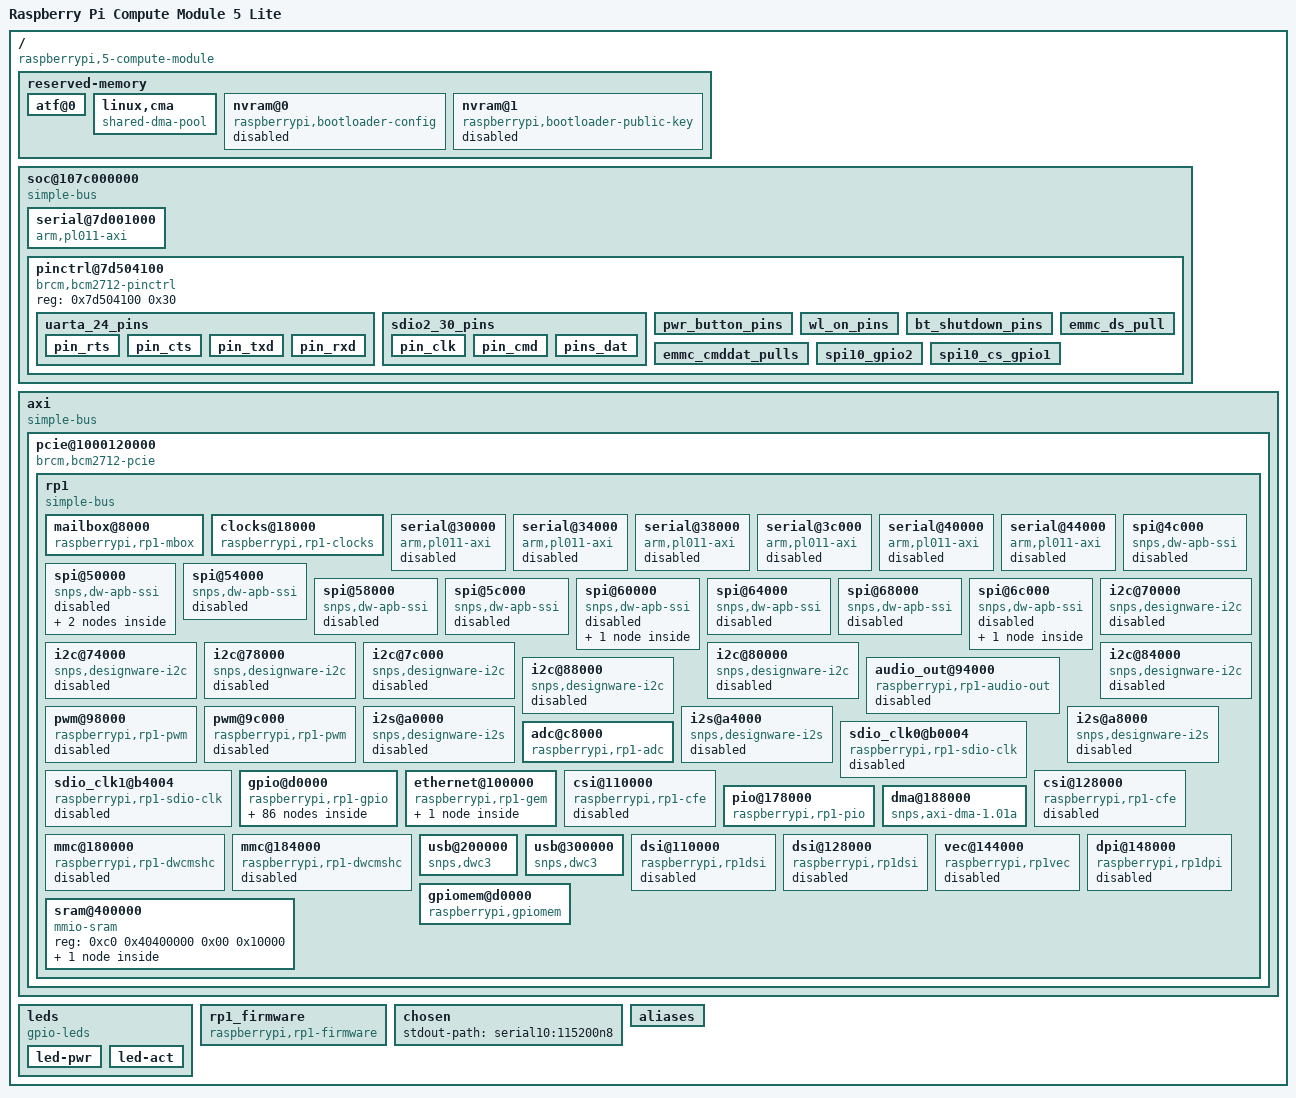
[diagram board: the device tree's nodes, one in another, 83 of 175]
/dts-v1/;
/*
 * Reduced stock Raspberry Pi CM5 Lite board DTB (bcm2712-rpi-cm5l-cm5io.dtb as the firmware ships
 * it; the upstream sources are GPL-2.0 OR MIT), decompiled with dtc. Kept: the root properties,
 * /reserved-memory, /axi/pcie@1000120000 with the whole RP1 subtree, the BCM2712 UART10 console
 * and pinctrl@7d504100, /leds, /rp1_firmware, /chosen stdout-path, and the /aliases and
 * /__symbols__ entries that point into them. Everything else is dropped, so phandles to removed
 * nodes (clocks, regulators, interrupt controllers outside RP1) dangle on purpose: the ownership
 * checks must not need them. Compile without -@ (the __symbols__ node is part of the source).
 */

/ {
	compatible = "raspberrypi,5-compute-module", "brcm,bcm2712";
	#address-cells = <0x02>;
	#size-cells = <0x01>;
	interrupt-parent = <0x01>;
	model = "Raspberry Pi Compute Module 5 Lite";
	reserved-memory {
		ranges;
		#address-cells = <0x02>;
		#size-cells = <0x01>;
		phandle = <0x80>;
		atf@0 {
			reg = <0x00 0x00 0x80000>;
			no-map;
		};
		linux,cma {
			compatible = "shared-dma-pool";
			size = <0x4000000>;
			reusable;
			linux,cma-default;
			alloc-ranges = <0x00 0x00 0x40000000>;
			phandle = <0x81>;
		};
		nvram@0 {
			compatible = "raspberrypi,bootloader-config", "nvmem-rmem";
			#address-cells = <0x01>;
			#size-cells = <0x01>;
			reg = <0x00 0x00 0x00>;
			no-map;
			status = "disabled";
			phandle = <0x82>;
		};
		nvram@1 {
			compatible = "raspberrypi,bootloader-public-key", "nvmem-rmem";
			#address-cells = <0x01>;
			#size-cells = <0x01>;
			reg = <0x00 0x00 0x00>;
			no-map;
			status = "disabled";
			phandle = <0x83>;
		};
	};
	soc@107c000000 {
		compatible = "simple-bus";
		ranges = <0x00 0x10 0x00 0x80000000>;
		#address-cells = <0x01>;
		#size-cells = <0x01>;
		phandle = <0x84>;
		serial@7d001000 {
			compatible = "arm,pl011-axi";
			reg = <0x7d001000 0x200>;
			interrupts = <0x00 0x79 0x04>;
			clocks = <0x0d 0x0e>;
			clock-names = "uartclk", "apb_pclk";
			arm,primecell-periphid = <0x341011>;
			status = "okay";
			phandle = <0x87>;
		};
		pinctrl@7d504100 {
			compatible = "brcm,bcm2712-pinctrl";
			reg = <0x7d504100 0x30>;
			phandle = <0x91>;
			uarta_24_pins {
				phandle = <0x1f>;
				pin_rts {
					function = "uart0";
					pins = "gpio24";
					bias-disable;
				};
				pin_cts {
					function = "uart0";
					pins = "gpio25";
					bias-pull-up;
				};
				pin_txd {
					function = "uart0";
					pins = "gpio26";
					bias-disable;
				};
				pin_rxd {
					function = "uart0";
					pins = "gpio27";
					bias-pull-up;
				};
			};
			sdio2_30_pins {
				phandle = <0x49>;
				pin_clk {
					function = "sd2";
					pins = "gpio30";
					bias-disable;
				};
				pin_cmd {
					function = "sd2";
					pins = "gpio31";
					bias-pull-up;
				};
				pins_dat {
					function = "sd2";
					pins = "gpio32", "gpio33", "gpio34", "gpio35";
					bias-pull-up;
				};
			};
			pwr_button_pins {
				function = "gpio";
				pins = "gpio20";
				bias-pull-up;
				phandle = <0x76>;
			};
			wl_on_pins {
				function = "gpio";
				pins = "gpio28";
				phandle = <0x5b>;
			};
			bt_shutdown_pins {
				function = "gpio";
				pins = "gpio29";
				phandle = <0x20>;
			};
			emmc_ds_pull {
				pins = "emmc_ds";
				bias-pull-down;
				phandle = <0x0a>;
			};
			emmc_cmddat_pulls {
				pins = "emmc_cmd", "emmc_dat0", "emmc_dat1", "emmc_dat2", "emmc_dat3", "emmc_dat4", "emmc_dat5", "emmc_dat6", "emmc_dat7";
				bias-pull-up;
				phandle = <0x09>;
			};
			spi10_gpio2 {
				function = "vc_spi0";
				pins = "gpio2", "gpio3", "gpio4";
				bias-disable;
				phandle = <0x1b>;
			};
			spi10_cs_gpio1 {
				function = "gpio";
				pins = "gpio1";
				bias-pull-up;
				phandle = <0x1c>;
			};
		};
	};
	axi {
		compatible = "simple-bus";
		#address-cells = <0x02>;
		#size-cells = <0x02>;
		ranges = <0x00 0x00 0x00 0x00 0x10 0x00 0x10 0x00 0x10 0x00 0x01 0x00 0x14 0x00 0x14 0x00 0x04 0x00 0x18 0x00 0x18 0x00 0x04 0x00 0x1c 0x00 0x1c 0x00 0x04 0x00>;
		dma-ranges = <0x00 0x00 0x00 0x00 0x10 0x00 0x10 0x00 0x10 0x00 0x01 0x00 0x14 0x00 0x14 0x00 0x04 0x00 0x18 0x00 0x18 0x00 0x04 0x00 0x1c 0x00 0x1c 0x00 0x04 0x00>;
		phandle = <0xa4>;
		pcie@1000120000 {
			compatible = "brcm,bcm2712-pcie";
			reg = <0x10 0x120000 0x00 0x9310>;
			device_type = "pci";
			linux,pci-domain = <0x02>;
			max-link-speed = <0x02>;
			num-lanes = <0x04>;
			#address-cells = <0x03>;
			#interrupt-cells = <0x01>;
			#size-cells = <0x02>;
			interrupt-parent = <0x01>;
			interrupts = <0x00 0xe9 0x04 0x00 0xea 0x04>;
			interrupt-names = "pcie", "msi";
			interrupt-map-mask = <0x00 0x00 0x00 0x07>;
			interrupt-map = <0x00 0x00 0x00 0x01 0x01 0x00 0xe5 0x04 0x00 0x00 0x00 0x02 0x01 0x00 0xe6 0x04 0x00 0x00 0x00 0x03 0x01 0x00 0xe7 0x04 0x00 0x00 0x00 0x04 0x01 0x00 0xe8 0x04>;
			resets = <0x22 0x23 0x2c>;
			reset-names = "rescal", "bridge";
			msi-controller;
			msi-parent = <0x26>;
			ranges = <0x2000000 0x00 0x00 0x1f 0x00 0x00 0xfffffffc 0x43000000 0x04 0x00 0x1c 0x00 0x03 0x00>;
			dma-ranges = <0x2000000 0x00 0x00 0x1f 0x00 0x00 0x400000 0x43000000 0x10 0x00 0x00 0x00 0x10 0x00 0x3000000 0xff 0xfffff000 0x10 0x130000 0x00 0x1000>;
			status = "okay";
			brcm,vdm-qos-map = <0x8080809 0xa0a0b0b>;
			aspm-no-l0s;
			phandle = <0xa6>;
			rp1 {
				compatible = "simple-bus";
				#address-cells = <0x02>;
				#size-cells = <0x02>;
				#interrupt-cells = <0x02>;
				interrupt-controller;
				interrupt-parent = <0x27>;
				ranges = <0xc0 0x40000000 0x2000000 0x00 0x00 0x00 0x410000>;
				dma-ranges = <0x10 0x00 0x43000000 0x10 0x00 0x10 0x00 0xc0 0x40000000 0x2000000 0x00 0x00 0x00 0x410000 0x00 0x00 0x2000000 0x10 0x00 0x10 0x00>;
				phandle = <0x27>;
				mailbox@8000 {
					compatible = "raspberrypi,rp1-mbox";
					status = "okay";
					reg = <0xc0 0x40008000 0x00 0x4000>;
					interrupts = <0x3a 0x04>;
					#mbox-cells = <0x01>;
					phandle = <0x5c>;
				};
				clocks@18000 {
					compatible = "raspberrypi,rp1-clocks";
					#clock-cells = <0x01>;
					reg = <0xc0 0x40018000 0x00 0x10038>;
					clocks = <0x28>;
					assigned-clocks = <0x02 0x00 0x02 0x01 0x02 0x03 0x02 0x09 0x02 0x10 0x02 0x04 0x02 0x0a 0x02 0x0c 0x02 0x06 0x02 0x0d 0x02 0x1f 0x02 0x20 0x02 0x1d>;
					assigned-clock-rates = <0x3b9aca00 0x5b8d8000 0xbebc200 0x7735940 0x7735940 0x3a98000 0x927c000 0xbebc200 0x5f5e100 0x2faf080 0xf4240 0xbebc200 0x2faf080>;
					phandle = <0x02>;
				};
				serial@30000 {
					compatible = "arm,pl011-axi";
					reg = <0xc0 0x40030000 0x00 0x100>;
					interrupts = <0x19 0x04>;
					clocks = <0x02 0x0f 0x02 0x06>;
					clock-names = "uartclk", "apb_pclk";
					pinctrl-names = "default";
					arm,primecell-periphid = <0x341011>;
					uart-has-rtscts;
					cts-event-workaround;
					skip-init;
					status = "disabled";
					pinctrl-0 = <0x29>;
					phandle = <0x70>;
				};
				serial@34000 {
					compatible = "arm,pl011-axi";
					reg = <0xc0 0x40034000 0x00 0x100>;
					interrupts = <0x2a 0x04>;
					clocks = <0x02 0x0f 0x02 0x06>;
					clock-names = "uartclk", "apb_pclk";
					pinctrl-names = "default";
					arm,primecell-periphid = <0x341011>;
					uart-has-rtscts;
					cts-event-workaround;
					skip-init;
					status = "disabled";
					phandle = <0xa7>;
				};
				serial@38000 {
					compatible = "arm,pl011-axi";
					reg = <0xc0 0x40038000 0x00 0x100>;
					interrupts = <0x2b 0x04>;
					clocks = <0x02 0x0f 0x02 0x06>;
					clock-names = "uartclk", "apb_pclk";
					pinctrl-names = "default";
					arm,primecell-periphid = <0x341011>;
					uart-has-rtscts;
					cts-event-workaround;
					skip-init;
					status = "disabled";
					phandle = <0xa8>;
				};
				serial@3c000 {
					compatible = "arm,pl011-axi";
					reg = <0xc0 0x4003c000 0x00 0x100>;
					interrupts = <0x2c 0x04>;
					clocks = <0x02 0x0f 0x02 0x06>;
					clock-names = "uartclk", "apb_pclk";
					pinctrl-names = "default";
					arm,primecell-periphid = <0x341011>;
					uart-has-rtscts;
					cts-event-workaround;
					skip-init;
					status = "disabled";
					phandle = <0xa9>;
				};
				serial@40000 {
					compatible = "arm,pl011-axi";
					reg = <0xc0 0x40040000 0x00 0x100>;
					interrupts = <0x2d 0x04>;
					clocks = <0x02 0x0f 0x02 0x06>;
					clock-names = "uartclk", "apb_pclk";
					pinctrl-names = "default";
					arm,primecell-periphid = <0x341011>;
					uart-has-rtscts;
					cts-event-workaround;
					skip-init;
					status = "disabled";
					phandle = <0xaa>;
				};
				serial@44000 {
					compatible = "arm,pl011-axi";
					reg = <0xc0 0x40044000 0x00 0x100>;
					interrupts = <0x2e 0x04>;
					clocks = <0x02 0x0f 0x02 0x06>;
					clock-names = "uartclk", "apb_pclk";
					pinctrl-names = "default";
					arm,primecell-periphid = <0x341011>;
					uart-has-rtscts;
					cts-event-workaround;
					skip-init;
					status = "disabled";
					phandle = <0xab>;
				};
				spi@4c000 {
					reg = <0xc0 0x4004c000 0x00 0x130>;
					compatible = "snps,dw-apb-ssi";
					interrupts = <0x38 0x04>;
					clocks = <0x02 0x0c>;
					clock-names = "ssi_clk";
					#address-cells = <0x01>;
					#size-cells = <0x00>;
					num-cs = <0x02>;
					dmas = <0x2a 0x37 0x2a 0x36>;
					dma-names = "tx", "rx";
					status = "disabled";
					phandle = <0xac>;
				};
				spi@50000 {
					reg = <0xc0 0x40050000 0x00 0x130>;
					compatible = "snps,dw-apb-ssi";
					interrupts = <0x13 0x04>;
					clocks = <0x02 0x0c>;
					clock-names = "ssi_clk";
					#address-cells = <0x01>;
					#size-cells = <0x00>;
					num-cs = <0x02>;
					dmas = <0x2a 0x0d 0x2a 0x0c>;
					dma-names = "tx", "rx";
					status = "disabled";
					pinctrl-names = "default";
					pinctrl-0 = <0x2b 0x2c>;
					cs-gpios = <0x2d 0x08 0x01 0x2d 0x07 0x01>;
					phandle = <0x6e>;
					spidev@0 {
						compatible = "spidev";
						reg = <0x00>;
						#address-cells = <0x01>;
						#size-cells = <0x00>;
						spi-max-frequency = <0x7735940>;
						phandle = <0xad>;
					};
					spidev@1 {
						compatible = "spidev";
						reg = <0x01>;
						#address-cells = <0x01>;
						#size-cells = <0x00>;
						spi-max-frequency = <0x7735940>;
						phandle = <0xae>;
					};
				};
				spi@54000 {
					reg = <0xc0 0x40054000 0x00 0x130>;
					compatible = "snps,dw-apb-ssi";
					interrupts = <0x14 0x04>;
					clocks = <0x02 0x0c>;
					clock-names = "ssi_clk";
					#address-cells = <0x01>;
					#size-cells = <0x00>;
					num-cs = <0x02>;
					dmas = <0x2a 0x0f 0x2a 0x0e>;
					dma-names = "tx", "rx";
					status = "disabled";
					phandle = <0xaf>;
				};
				spi@58000 {
					reg = <0xc0 0x40058000 0x00 0x130>;
					compatible = "snps,dw-apb-ssi";
					interrupts = <0x15 0x04>;
					clocks = <0x02 0x0c>;
					clock-names = "ssi_clk";
					#address-cells = <0x01>;
					#size-cells = <0x00>;
					num-cs = <0x02>;
					dmas = <0x2a 0x11 0x2a 0x10>;
					dma-names = "tx", "rx";
					status = "disabled";
					pinctrl-names = "default";
					pinctrl-0 = <0x2e>;
					phandle = <0xb0>;
				};
				spi@5c000 {
					reg = <0xc0 0x4005c000 0x00 0x130>;
					compatible = "snps,dw-apb-ssi";
					interrupts = <0x16 0x04>;
					clocks = <0x02 0x0c>;
					clock-names = "ssi_clk";
					#address-cells = <0x01>;
					#size-cells = <0x00>;
					num-cs = <0x02>;
					dmas = <0x2a 0x13 0x2a 0x12>;
					dma-names = "tx", "rx";
					status = "disabled";
					pinctrl-names = "default";
					pinctrl-0 = <0x2f>;
					phandle = <0xb1>;
				};
				spi@60000 {
					reg = <0xc0 0x40060000 0x00 0x130>;
					compatible = "snps,dw-apb-ssi";
					interrupts = <0x17 0x04>;
					clocks = <0x02 0x0c>;
					clock-names = "ssi_clk";
					#address-cells = <0x00>;
					#size-cells = <0x00>;
					num-cs = <0x01>;
					spi-slave;
					dmas = <0x2a 0x15 0x2a 0x14>;
					dma-names = "tx", "rx";
					status = "disabled";
					pinctrl-names = "default";
					pinctrl-0 = <0x30>;
					phandle = <0xb2>;
					slave {
						compatible = "spidev";
						spi-max-frequency = <0xf4240>;
					};
				};
				spi@64000 {
					reg = <0xc0 0x40064000 0x00 0x130>;
					compatible = "snps,dw-apb-ssi";
					interrupts = <0x18 0x04>;
					clocks = <0x02 0x0c>;
					clock-names = "ssi_clk";
					#address-cells = <0x01>;
					#size-cells = <0x00>;
					num-cs = <0x02>;
					dmas = <0x2a 0x17 0x2a 0x16>;
					dma-names = "tx", "rx";
					status = "disabled";
					pinctrl-names = "default";
					pinctrl-0 = <0x31>;
					phandle = <0xb3>;
				};
				spi@68000 {
					reg = <0xc0 0x40068000 0x00 0x130>;
					compatible = "snps,dw-apb-ssi";
					interrupts = <0x36 0x04>;
					clocks = <0x02 0x0c>;
					clock-names = "ssi_clk";
					#address-cells = <0x01>;
					#size-cells = <0x00>;
					num-cs = <0x02>;
					dmas = <0x2a 0x33 0x2a 0x32>;
					dma-names = "tx", "rx";
					status = "disabled";
					phandle = <0xb4>;
				};
				spi@6c000 {
					reg = <0xc0 0x4006c000 0x00 0x130>;
					compatible = "snps,dw-apb-ssi";
					interrupts = <0x37 0x04>;
					clocks = <0x02 0x0c>;
					clock-names = "ssi_clk";
					#address-cells = <0x00>;
					#size-cells = <0x00>;
					num-cs = <0x01>;
					spi-slave;
					dmas = <0x2a 0x35 0x2a 0x34>;
					dma-names = "tx", "rx";
					status = "disabled";
					phandle = <0xb5>;
					slave {
						compatible = "spidev";
						spi-max-frequency = <0xf4240>;
					};
				};
				i2c@70000 {
					reg = <0xc0 0x40070000 0x00 0x1000>;
					compatible = "snps,designware-i2c";
					interrupts = <0x07 0x04>;
					clocks = <0x02 0x0c>;
					i2c-scl-rising-time-ns = <0x41>;
					i2c-scl-falling-time-ns = <0x64>;
					status = "disabled";
					pinctrl-0 = <0x32>;
					pinctrl-names = "default";
					clock-frequency = <0x186a0>;
					symlink = "i2c-11";
					phandle = <0x65>;
				};
				i2c@74000 {
					reg = <0xc0 0x40074000 0x00 0x1000>;
					compatible = "snps,designware-i2c";
					interrupts = <0x08 0x04>;
					clocks = <0x02 0x0c>;
					i2c-scl-rising-time-ns = <0x41>;
					i2c-scl-falling-time-ns = <0x64>;
					status = "disabled";
					pinctrl-names = "default";
					pinctrl-0 = <0x33>;
					clock-frequency = <0x186a0>;
					phandle = <0x64>;
				};
				i2c@78000 {
					reg = <0xc0 0x40078000 0x00 0x1000>;
					compatible = "snps,designware-i2c";
					interrupts = <0x09 0x04>;
					clocks = <0x02 0x0c>;
					i2c-scl-rising-time-ns = <0x41>;
					i2c-scl-falling-time-ns = <0x64>;
					status = "disabled";
					pinctrl-names = "default";
					pinctrl-0 = <0x34>;
					phandle = <0xb6>;
				};
				i2c@7c000 {
					reg = <0xc0 0x4007c000 0x00 0x1000>;
					compatible = "snps,designware-i2c";
					interrupts = <0x0a 0x04>;
					clocks = <0x02 0x0c>;
					i2c-scl-rising-time-ns = <0x41>;
					i2c-scl-falling-time-ns = <0x64>;
					status = "disabled";
					pinctrl-names = "default";
					pinctrl-0 = <0x35>;
					phandle = <0xb7>;
				};
				i2c@80000 {
					reg = <0xc0 0x40080000 0x00 0x1000>;
					compatible = "snps,designware-i2c";
					interrupts = <0x0b 0x04>;
					clocks = <0x02 0x0c>;
					i2c-scl-rising-time-ns = <0x41>;
					i2c-scl-falling-time-ns = <0x64>;
					status = "disabled";
					phandle = <0xb8>;
				};
				i2c@84000 {
					reg = <0xc0 0x40084000 0x00 0x1000>;
					compatible = "snps,designware-i2c";
					interrupts = <0x0c 0x04>;
					clocks = <0x02 0x0c>;
					i2c-scl-rising-time-ns = <0x41>;
					i2c-scl-falling-time-ns = <0x64>;
					status = "disabled";
					phandle = <0xb9>;
				};
				i2c@88000 {
					reg = <0xc0 0x40088000 0x00 0x1000>;
					compatible = "snps,designware-i2c";
					interrupts = <0x0d 0x04>;
					clocks = <0x02 0x0c>;
					i2c-scl-rising-time-ns = <0x41>;
					i2c-scl-falling-time-ns = <0x64>;
					status = "disabled";
					pinctrl-0 = <0x36>;
					pinctrl-names = "default";
					clock-frequency = <0x186a0>;
					symlink = "i2c-6";
					phandle = <0x66>;
				};
				audio_out@94000 {
					compatible = "raspberrypi,rp1-audio-out";
					reg = <0xc0 0x40094000 0x00 0x4000>;
					clocks = <0x02 0x14>;
					assigned-clocks = <0x02 0x14>;
					assigned-clock-rates = <0x927c000>;
					assigned-clock-parents = <0x02 0x0a>;
					dmas = <0x2a 0x1d>;
					dma-maxburst = <0x04>;
					dma-names = "tx";
					#sound-dai-cells = <0x00>;
					status = "disabled";
					phandle = <0xba>;
				};
				pwm@98000 {
					compatible = "raspberrypi,rp1-pwm";
					reg = <0xc0 0x40098000 0x00 0x100>;
					#pwm-cells = <0x03>;
					clocks = <0x02 0x11>;
					assigned-clocks = <0x02 0x11>;
					assigned-clock-rates = <0x2faf080>;
					status = "disabled";
					phandle = <0xbb>;
				};
				pwm@9c000 {
					compatible = "raspberrypi,rp1-pwm";
					reg = <0xc0 0x4009c000 0x00 0x100>;
					#pwm-cells = <0x03>;
					clocks = <0x02 0x12>;
					assigned-clocks = <0x02 0x12>;
					assigned-clock-rates = <0x2faf080>;
					status = "disabled";
					pinctrl-0 = <0x37>;
					pinctrl-names = "default";
					phandle = <0x62>;
				};
				i2s@a0000 {
					reg = <0xc0 0x400a0000 0x00 0x1000>;
					compatible = "snps,designware-i2s";
					clocks = <0x02 0x15>;
					clock-names = "i2sclk";
					#sound-dai-cells = <0x00>;
					dmas = <0x2a 0x20 0x2a 0x1f>;
					dma-names = "tx", "rx";
					dma-maxburst = <0x04>;
					status = "disabled";
					pinctrl-names = "default";
					pinctrl-0 = <0x38>;
					phandle = <0xbc>;
				};
				i2s@a4000 {
					reg = <0xc0 0x400a4000 0x00 0x1000>;
					compatible = "snps,designware-i2s";
					clocks = <0x02 0x15>;
					clock-names = "i2sclk";
					#sound-dai-cells = <0x00>;
					dmas = <0x2a 0x22 0x2a 0x21>;
					dma-names = "tx", "rx";
					dma-maxburst = <0x04>;
					status = "disabled";
					pinctrl-names = "default";
					pinctrl-0 = <0x39>;
					phandle = <0xbd>;
				};
				i2s@a8000 {
					reg = <0xc0 0x400a8000 0x00 0x1000>;
					compatible = "snps,designware-i2s";
					clocks = <0x02 0x15>;
					status = "disabled";
					phandle = <0xbe>;
				};
				sdio_clk0@b0004 {
					compatible = "raspberrypi,rp1-sdio-clk";
					reg = <0xc0 0x400b0004 0x00 0x1c>;
					clocks = <0x3a 0x3b>;
					clock-names = "src", "base";
					#clock-cells = <0x00>;
					status = "disabled";
					phandle = <0x41>;
				};
				sdio_clk1@b4004 {
					compatible = "raspberrypi,rp1-sdio-clk";
					reg = <0xc0 0x400b4004 0x00 0x1c>;
					clocks = <0x3a 0x3b>;
					clock-names = "src", "base";
					#clock-cells = <0x00>;
					status = "disabled";
					phandle = <0x42>;
				};
				adc@c8000 {
					compatible = "raspberrypi,rp1-adc";
					reg = <0xc0 0x400c8000 0x00 0x4000>;
					clocks = <0x02 0x1e>;
					clock-names = "adcclk";
					#clock-cells = <0x00>;
					vref-supply = <0x3c>;
					status = "okay";
					phandle = <0xbf>;
				};
				gpio@d0000 {
					reg = <0xc0 0x400d0000 0x00 0xc000 0xc0 0x400e0000 0x00 0xc000 0xc0 0x400f0000 0x00 0xc000>;
					compatible = "raspberrypi,rp1-gpio";
					interrupts = <0x00 0x04 0x01 0x04 0x02 0x04>;
					gpio-controller;
					#gpio-cells = <0x02>;
					interrupt-controller;
					#interrupt-cells = <0x02>;
					gpio-ranges = <0x2d 0x00 0x00 0x36>;
					status = "okay";
					gpio-line-names = "ID_SDA", "ID_SCL", "GPIO2", "GPIO3", "GPIO4", "GPIO5", "GPIO6", "GPIO7", "GPIO8", "GPIO9", "GPIO10", "GPIO11", "GPIO12", "GPIO13", "GPIO14", "GPIO15", "GPIO16", "GPIO17", "GPIO18", "GPIO19", "GPIO20", "GPIO21", "GPIO22", "GPIO23", "GPIO24", "GPIO25", "GPIO26", "GPIO27", "PCIE_PWR_EN", "FAN_TACH", "HOST_SDA", "HOST_SCL", "ETH_RST_N", "PCIE_DET_WAKE", "CD0_IO0_MICCLK", "CD0_IO0_MICDAT0", "RP1_PCIE_CLKREQ_N", "ETH_IRQ_N", "SDA0", "SCL0", "-", "-", "USB_VBUS_EN", "-", "RP1_STAT_LED", "FAN_PWM", "-", "2712_WAKE", "-", "-", "-", "-", "-", "-";
					phandle = <0x2d>;
					rp1_uart0_14_15 {
						phandle = <0x29>;
						pin_txd {
							function = "uart0";
							pins = "gpio14";
							bias-disable;
						};
						pin_rxd {
							function = "uart0";
							pins = "gpio15";
							bias-pull-up;
						};
					};
					rp1_uart0_ctsrts_16_17 {
						phandle = <0xc0>;
						pin_cts {
							function = "uart0";
							pins = "gpio16";
							bias-pull-up;
						};
						pin_rts {
							function = "uart0";
							pins = "gpio17";
							bias-disable;
						};
					};
					rp1_uart1_0_1 {
						phandle = <0xc1>;
						pin_txd {
							function = "uart1";
							pins = "gpio0";
							bias-disable;
						};
						pin_rxd {
							function = "uart1";
							pins = "gpio1";
							bias-pull-up;
						};
					};
					rp1_uart1_ctsrts_2_3 {
						phandle = <0xc2>;
						pin_cts {
							function = "uart1";
							pins = "gpio2";
							bias-pull-up;
						};
						pin_rts {
							function = "uart1";
							pins = "gpio3";
							bias-disable;
						};
					};
					rp1_uart2_4_5 {
						phandle = <0xc3>;
						pin_txd {
							function = "uart2";
							pins = "gpio4";
							bias-disable;
						};
						pin_rxd {
							function = "uart2";
							pins = "gpio5";
							bias-pull-up;
						};
					};
					rp1_uart2_ctsrts_6_7 {
						phandle = <0xc4>;
						pin_cts {
							function = "uart2";
							pins = "gpio6";
							bias-pull-up;
						};
						pin_rts {
							function = "uart2";
							pins = "gpio7";
							bias-disable;
						};
					};
					rp1_uart3_8_9 {
						phandle = <0xc5>;
						pin_txd {
							function = "uart3";
							pins = "gpio8";
							bias-disable;
						};
						pin_rxd {
							function = "uart3";
							pins = "gpio9";
							bias-pull-up;
						};
					};
					rp1_uart3_ctsrts_10_11 {
						phandle = <0xc6>;
						pin_cts {
							function = "uart3";
							pins = "gpio10";
							bias-pull-up;
						};
						pin_rts {
							function = "uart3";
							pins = "gpio11";
							bias-disable;
						};
					};
					rp1_uart4_12_13 {
						phandle = <0xc7>;
						pin_txd {
							function = "uart4";
							pins = "gpio12";
							bias-disable;
						};
						pin_rxd {
							function = "uart4";
							pins = "gpio13";
							bias-pull-up;
						};
					};
					rp1_uart4_ctsrts_14_15 {
						phandle = <0xc8>;
						pin_cts {
							function = "uart4";
							pins = "gpio14";
							bias-pull-up;
						};
						pin_rts {
							function = "uart4";
							pins = "gpio15";
							bias-disable;
						};
					};
					rp1_sdio0_22_27 {
						phandle = <0xc9>;
						pin_clk {
							function = "sd0";
							pins = "gpio22";
							bias-disable;
							drive-strength = <0x0c>;
							slew-rate = <0x01>;
						};
						pin_cmd {
							function = "sd0";
							pins = "gpio23";
							bias-pull-up;
							drive-strength = <0x0c>;
							slew-rate = <0x01>;
						};
						pins_dat {
							function = "sd0";
							pins = "gpio24", "gpio25", "gpio26", "gpio27";
							bias-pull-up;
							drive-strength = <0x0c>;
							slew-rate = <0x01>;
						};
					};
					rp1_sdio1_28_33 {
						phandle = <0xca>;
						pin_clk {
							function = "sd1";
							pins = "gpio28";
							bias-disable;
							drive-strength = <0x0c>;
							slew-rate = <0x01>;
						};
						pin_cmd {
							function = "sd1";
							pins = "gpio29";
							bias-pull-up;
							drive-strength = <0x0c>;
							slew-rate = <0x01>;
						};
						pins_dat {
							function = "sd1";
							pins = "gpio30", "gpio31", "gpio32", "gpio33";
							bias-pull-up;
							drive-strength = <0x0c>;
							slew-rate = <0x01>;
						};
					};
					rp1_i2s0_18_21 {
						function = "i2s0";
						pins = "gpio18", "gpio19", "gpio20", "gpio21";
						bias-disable;
						phandle = <0x38>;
					};
					rp1_i2s1_18_21 {
						function = "i2s1";
						pins = "gpio18", "gpio19", "gpio20", "gpio21";
						bias-disable;
						phandle = <0x39>;
					};
					rp1_i2c4_34_35 {
						function = "i2c4";
						pins = "gpio34", "gpio35";
						drive-strength = <0x0c>;
						bias-pull-up;
						phandle = <0xcb>;
					};
					rp1_i2c6_38_39 {
						function = "i2c6";
						pins = "gpio38", "gpio39";
						drive-strength = <0x0c>;
						bias-pull-up;
						phandle = <0x36>;
					};
					rp1_i2c4_40_41 {
						function = "i2c4";
						pins = "gpio40", "gpio41";
						drive-strength = <0x0c>;
						bias-pull-up;
						phandle = <0xcc>;
					};
					rp1_i2c5_44_45 {
						function = "i2c5";
						pins = "gpio44", "gpio45";
						drive-strength = <0x0c>;
						bias-pull-up;
						phandle = <0xcd>;
					};
					rp1_i2c0_0_1 {
						function = "i2c0";
						pins = "gpio0", "gpio1";
						drive-strength = <0x0c>;
						bias-pull-up;
						phandle = <0x32>;
					};
					rp1_i2c0_8_9 {
						function = "i2c0";
						pins = "gpio8", "gpio9";
						drive-strength = <0x0c>;
						bias-pull-up;
						phandle = <0xce>;
					};
					rp1_i2c1_2_3 {
						function = "i2c1";
						pins = "gpio2", "gpio3";
						drive-strength = <0x0c>;
						bias-pull-up;
						phandle = <0x33>;
					};
					rp1_i2c1_10_11 {
						function = "i2c1";
						pins = "gpio10", "gpio11";
						drive-strength = <0x0c>;
						bias-pull-up;
						phandle = <0xcf>;
					};
					rp1_i2c2_4_5 {
						function = "i2c2";
						pins = "gpio4", "gpio5";
						drive-strength = <0x0c>;
						bias-pull-up;
						phandle = <0x34>;
					};
					rp1_i2c2_12_13 {
						function = "i2c2";
						pins = "gpio12", "gpio13";
						drive-strength = <0x0c>;
						bias-pull-up;
						phandle = <0xd0>;
					};
					rp1_i2c3_6_7 {
						function = "i2c3";
						pins = "gpio6", "gpio7";
						drive-strength = <0x0c>;
						bias-pull-up;
						phandle = <0x35>;
					};
					rp1_i2c3_14_15 {
						function = "i2c3";
						pins = "gpio14", "gpio15";
						drive-strength = <0x0c>;
						bias-pull-up;
						phandle = <0xd1>;
					};
					rp1_i2c3_22_23 {
						function = "i2c3";
						pins = "gpio22", "gpio23";
						drive-strength = <0x0c>;
						bias-pull-up;
						phandle = <0xd2>;
					};
					rp1_dpi_16bit_gpio2 {
						function = "dpi";
						pins = "gpio2", "gpio3", "gpio4", "gpio5", "gpio6", "gpio7", "gpio8", "gpio9", "gpio10", "gpio11", "gpio12", "gpio13", "gpio14", "gpio15", "gpio16", "gpio17", "gpio18", "gpio19";
						bias-disable;
						phandle = <0xd3>;
					};
					rp1_dpi_16bit_cpadhi_gpio2 {
						function = "dpi";
						pins = "gpio2", "gpio3", "gpio4", "gpio5", "gpio6", "gpio7", "gpio8", "gpio12", "gpio13", "gpio14", "gpio15", "gpio16", "gpio17", "gpio20", "gpio21", "gpio22", "gpio23", "gpio24";
						bias-disable;
						phandle = <0xd4>;
					};
					rp1_dpi_16bit_pad666_gpio2 {
						function = "dpi";
						pins = "gpio2", "gpio3", "gpio5", "gpio6", "gpio7", "gpio8", "gpio9", "gpio12", "gpio13", "gpio14", "gpio15", "gpio16", "gpio17", "gpio21", "gpio22", "gpio23", "gpio24", "gpio25";
						bias-disable;
						phandle = <0xd5>;
					};
					rp1_dpi_18bit_gpio2 {
						function = "dpi";
						pins = "gpio2", "gpio3", "gpio4", "gpio5", "gpio6", "gpio7", "gpio8", "gpio9", "gpio10", "gpio11", "gpio12", "gpio13", "gpio14", "gpio15", "gpio16", "gpio17", "gpio18", "gpio19", "gpio20", "gpio21";
						bias-disable;
						phandle = <0xd6>;
					};
					rp1_dpi_18bit_cpadhi_gpio2 {
						function = "dpi";
						pins = "gpio2", "gpio3", "gpio4", "gpio5", "gpio6", "gpio7", "gpio8", "gpio9", "gpio12", "gpio13", "gpio14", "gpio15", "gpio16", "gpio17", "gpio20", "gpio21", "gpio22", "gpio23", "gpio24", "gpio25";
						bias-disable;
						phandle = <0xd7>;
					};
					rp1_dpi_24bit_gpio2 {
						function = "dpi";
						pins = "gpio2", "gpio3", "gpio4", "gpio5", "gpio6", "gpio7", "gpio8", "gpio9", "gpio10", "gpio11", "gpio12", "gpio13", "gpio14", "gpio15", "gpio16", "gpio17", "gpio18", "gpio19", "gpio20", "gpio21", "gpio22", "gpio23", "gpio24", "gpio25", "gpio26", "gpio27";
						bias-disable;
						phandle = <0xd8>;
					};
					rp1_dpi_hvsync {
						function = "dpi";
						pins = "gpio2", "gpio3";
						bias-disable;
						phandle = <0xd9>;
					};
					rp1_dpi_16bit_gpio0 {
						function = "dpi";
						pins = "gpio0", "gpio1", "gpio2", "gpio3", "gpio4", "gpio5", "gpio6", "gpio7", "gpio8", "gpio9", "gpio10", "gpio11", "gpio12", "gpio13", "gpio14", "gpio15", "gpio16", "gpio17", "gpio18", "gpio19";
						bias-disable;
						phandle = <0xda>;
					};
					rp1_dpi_16bit_cpadhi_gpio0 {
						function = "dpi";
						pins = "gpio0", "gpio1", "gpio2", "gpio3", "gpio4", "gpio5", "gpio6", "gpio7", "gpio8", "gpio12", "gpio13", "gpio14", "gpio15", "gpio16", "gpio17", "gpio20", "gpio21", "gpio22", "gpio23", "gpio24";
						bias-disable;
						phandle = <0xdb>;
					};
					rp1_dpi_16bit_pad666_gpio0 {
						function = "dpi";
						pins = "gpio0", "gpio1", "gpio2", "gpio3", "gpio5", "gpio6", "gpio7", "gpio8", "gpio9", "gpio12", "gpio13", "gpio14", "gpio15", "gpio16", "gpio17", "gpio21", "gpio22", "gpio23", "gpio24", "gpio25";
						bias-disable;
						phandle = <0xdc>;
					};
					rp1_dpi_18bit_gpio0 {
						function = "dpi";
						pins = "gpio0", "gpio1", "gpio2", "gpio3", "gpio4", "gpio5", "gpio6", "gpio7", "gpio8", "gpio9", "gpio10", "gpio11", "gpio12", "gpio13", "gpio14", "gpio15", "gpio16", "gpio17", "gpio18", "gpio19", "gpio20", "gpio21";
						bias-disable;
						phandle = <0xdd>;
					};
					rp1_dpi_18bit_cpadhi_gpio0 {
						function = "dpi";
						pins = "gpio0", "gpio1", "gpio2", "gpio3", "gpio4", "gpio5", "gpio6", "gpio7", "gpio8", "gpio9", "gpio12", "gpio13", "gpio14", "gpio15", "gpio16", "gpio17", "gpio20", "gpio21", "gpio22", "gpio23", "gpio24", "gpio25";
						bias-disable;
						phandle = <0xde>;
					};
					rp1_dpi_24bit_gpio0 {
						function = "dpi";
						pins = "gpio0", "gpio1", "gpio2", "gpio3", "gpio4", "gpio5", "gpio6", "gpio7", "gpio8", "gpio9", "gpio10", "gpio11", "gpio12", "gpio13", "gpio14", "gpio15", "gpio16", "gpio17", "gpio18", "gpio19", "gpio20", "gpio21", "gpio22", "gpio23", "gpio24", "gpio25", "gpio26", "gpio27";
						bias-disable;
						phandle = <0xdf>;
					};
					rp1_gpclksrc0_gpio4 {
						function = "gpclk0";
						pins = "gpio4";
						bias-disable;
						phandle = <0xe0>;
					};
					rp1_gpclksrc0_gpio20 {
						function = "gpclk0";
						pins = "gpio20";
						bias-disable;
						phandle = <0xe1>;
					};
					rp1_gpclksrc1_gpio5 {
						function = "gpclk1";
						pins = "gpio5";
						bias-disable;
						phandle = <0xe2>;
					};
					rp1_gpclksrc1_gpio18 {
						function = "gpclk1";
						pins = "gpio18";
						bias-disable;
						phandle = <0xe3>;
					};
					rp1_gpclksrc1_gpio21 {
						function = "gpclk1";
						pins = "gpio21";
						bias-disable;
						phandle = <0xe4>;
					};
					rp1_pwm1_gpio45 {
						function = "pwm1";
						pins = "gpio45";
						bias-pull-down;
						phandle = <0x37>;
					};
					rp1_spi0_gpio9 {
						function = "spi0";
						pins = "gpio9", "gpio10", "gpio11";
						bias-disable;
						drive-strength = <0x0c>;
						slew-rate = <0x01>;
						phandle = <0x2b>;
					};
					rp1_spi0_cs_gpio7 {
						function = "spi0";
						pins = "gpio7", "gpio8";
						bias-pull-up;
						phandle = <0x2c>;
					};
					rp1_spi1_gpio19 {
						function = "spi1";
						pins = "gpio19", "gpio20", "gpio21";
						bias-disable;
						drive-strength = <0x0c>;
						slew-rate = <0x01>;
						phandle = <0xe5>;
					};
					rp1_spi2_gpio1 {
						function = "spi2";
						pins = "gpio1", "gpio2", "gpio3";
						bias-disable;
						drive-strength = <0x0c>;
						slew-rate = <0x01>;
						phandle = <0x2e>;
					};
					rp1_spi3_gpio5 {
						function = "spi3";
						pins = "gpio5", "gpio6", "gpio7";
						bias-disable;
						drive-strength = <0x0c>;
						slew-rate = <0x01>;
						phandle = <0x2f>;
					};
					rp1_spi4_gpio9 {
						function = "spi4";
						pins = "gpio9", "gpio10", "gpio11";
						bias-disable;
						drive-strength = <0x0c>;
						slew-rate = <0x01>;
						phandle = <0x30>;
					};
					rp1_spi5_gpio13 {
						function = "spi5";
						pins = "gpio13", "gpio14", "gpio15";
						bias-disable;
						drive-strength = <0x0c>;
						slew-rate = <0x01>;
						phandle = <0x31>;
					};
					rp1_spi8_gpio49 {
						function = "spi8";
						pins = "gpio49", "gpio50", "gpio51";
						bias-disable;
						drive-strength = <0x0c>;
						slew-rate = <0x01>;
						phandle = <0xe6>;
					};
					rp1_spi8_cs_gpio52 {
						function = "spi0";
						pins = "gpio52", "gpio53";
						bias-pull-up;
						phandle = <0xe7>;
					};
					rp1_audio_out_12_13 {
						function = "aaud";
						pins = "gpio12", "gpio13";
						bias-disable;
						phandle = <0xe8>;
					};
					usb_vbus_pins {
						function = "vbus1";
						pins = "gpio42", "gpio43";
						phandle = <0x43>;
					};
					micclk1_hog {
						gpio-hog;
						gpios = <0x2e 0x00>;
						output-high;
					};
					micdat1_hog {
						gpio-hog;
						gpios = <0x30 0x00>;
						output-high;
					};
					eth0_irq_pins {
						pins = "gpio37";
						function = "gpio";
						bias-pull-up;
						input-enable;
						phandle = <0x3e>;
					};
				};
				ethernet@100000 {
					reg = <0xc0 0x40100000 0x00 0x4000>;
					compatible = "raspberrypi,rp1-gem", "cdns,macb";
					#address-cells = <0x01>;
					#size-cells = <0x00>;
					interrupts = <0x06 0x04>;
					clocks = <0x02 0x0c 0x02 0x0c 0x02 0x1d 0x02 0x10>;
					clock-names = "pclk", "hclk", "tsu_clk", "tx_clk";
					phy-mode = "rgmii-id";
					cdns,aw2w-max-pipe = [08];
					cdns,ar2r-max-pipe = [08];
					cdns,use-aw2b-fill;
					local-mac-address = [00 00 00 00 00 00];
					status = "okay";
					phy-handle = <0x3d>;
					phy-reset-gpios = <0x2d 0x20 0x01>;
					phy-reset-duration = <0x05>;
					pinctrl-names = "default";
					pinctrl-0 = <0x3e>;
					phandle = <0xe9>;
					ethernet-phy@0 {
						reg = <0x00>;
						brcm,powerdown-enable;
						interrupt-parent = <0x2d>;
						interrupts = <0x25 0x08>;
						eee-broken-1000t;
						eee-broken-100tx;
						phandle = <0x3d>;
					};
				};
				csi@110000 {
					compatible = "raspberrypi,rp1-cfe";
					reg = <0xc0 0x40110000 0x00 0x100 0xc0 0x40114000 0x00 0x100 0xc0 0x40120000 0x00 0x100 0xc0 0x40124000 0x00 0x1000>;
					interrupts = <0x2f 0x04>;
					clocks = <0x02 0x16>;
					assigned-clocks = <0x02 0x16>;
					assigned-clock-rates = <0x17d7840>;
					#address-cells = <0x01>;
					#size-cells = <0x00>;
					status = "disabled";
					iommus = <0x3f>;
					phandle = <0xea>;
				};
				csi@128000 {
					compatible = "raspberrypi,rp1-cfe";
					reg = <0xc0 0x40128000 0x00 0x100 0xc0 0x4012c000 0x00 0x100 0xc0 0x40138000 0x00 0x100 0xc0 0x4013c000 0x00 0x1000>;
					interrupts = <0x30 0x04>;
					clocks = <0x02 0x17>;
					assigned-clocks = <0x02 0x17>;
					assigned-clock-rates = <0x17d7840>;
					#address-cells = <0x01>;
					#size-cells = <0x00>;
					status = "disabled";
					iommus = <0x3f>;
					phandle = <0xeb>;
				};
				pio@178000 {
					reg = <0xc0 0x40178000 0x00 0x20>;
					compatible = "raspberrypi,rp1-pio";
					firmware = <0x40>;
					dmas = <0x2a 0x138 0x2a 0x139 0x2a 0x13a 0x2a 0x13b 0x2a 0x13c 0x2a 0x13d 0x2a 0x13e 0x2a 0x13f>;
					dma-names = "tx0", "rx0", "tx1", "rx1", "tx2", "rx2", "tx3", "rx3";
					status = "okay";
					phandle = <0xec>;
				};
				mmc@180000 {
					reg = <0xc0 0x40180000 0x00 0x100>;
					compatible = "raspberrypi,rp1-dwcmshc";
					interrupts = <0x11 0x04>;
					clocks = <0x02 0x0c 0x3b 0x02 0x1f 0x41>;
					clock-names = "bus", "core", "timeout", "sdio";
					no-1-8-v;
					bus-width = <0x04>;
					vmmc-supply = <0x3c>;
					broken-cd;
					status = "disabled";
					phandle = <0xed>;
				};
				mmc@184000 {
					reg = <0xc0 0x40184000 0x00 0x100>;
					compatible = "raspberrypi,rp1-dwcmshc";
					interrupts = <0x12 0x04>;
					clocks = <0x02 0x0c 0x3b 0x02 0x1f 0x42>;
					clock-names = "bus", "core", "timeout", "sdio";
					bus-width = <0x04>;
					vmmc-supply = <0x3c>;
					sdhci-caps-mask = <0x03 0x00>;
					broken-cd;
					status = "disabled";
					phandle = <0xee>;
				};
				dma@188000 {
					reg = <0xc0 0x40188000 0x00 0x1000>;
					compatible = "snps,axi-dma-1.01a";
					interrupts = <0x28 0x04>;
					clocks = <0x02 0x0e 0x02 0x0c>;
					clock-names = "core-clk", "cfgr-clk";
					#dma-cells = <0x01>;
					dma-channels = <0x08>;
					snps,dma-masters = <0x01>;
					snps,dma-targets = <0x40>;
					snps,data-width = <0x04>;
					snps,block-size = <0x40000 0x40000 0x40000 0x40000 0x40000 0x40000 0x40000 0x40000>;
					snps,priority = <0x00 0x01 0x02 0x03 0x04 0x05 0x06 0x07>;
					snps,axi-max-burst-len = <0x08 0x08 0x04 0x04 0x04 0x04 0x04 0x04>;
					status = "okay";
					snps,chan-flags = <0x100 0x100 0x00 0x00 0x00 0x00 0x00 0x00>;
					phandle = <0x2a>;
				};
				usb@200000 {
					reg = <0xc0 0x40200000 0x00 0x100000>;
					compatible = "snps,dwc3";
					dr_mode = "host";
					usb3-lpm-capable;
					snps,axi-pipe-limit = [08];
					snps,dis_rxdet_inp3_quirk;
					snps,enhanced-nak-fs-quirk;
					snps,parkmode-disable-ss-quirk;
					snps,parkmode-disable-hs-quirk;
					snps,parkmode-disable-fsls-quirk;
					snps,tx-max-burst = [08];
					snps,tx-thr-num-pkt = [02];
					interrupts = <0x1f 0x01>;
					status = "okay";
					pinctrl-0 = <0x43>;
					pinctrl-names = "default";
					phandle = <0xef>;
				};
				usb@300000 {
					reg = <0xc0 0x40300000 0x00 0x100000>;
					compatible = "snps,dwc3";
					dr_mode = "host";
					usb3-lpm-capable;
					snps,axi-pipe-limit = [08];
					snps,dis_rxdet_inp3_quirk;
					snps,enhanced-nak-fs-quirk;
					snps,parkmode-disable-ss-quirk;
					snps,parkmode-disable-hs-quirk;
					snps,parkmode-disable-fsls-quirk;
					snps,tx-max-burst = [08];
					snps,tx-thr-num-pkt = [02];
					interrupts = <0x24 0x01>;
					status = "okay";
					phandle = <0xf0>;
				};
				dsi@110000 {
					compatible = "raspberrypi,rp1dsi";
					status = "disabled";
					reg = <0xc0 0x40118000 0x00 0x1000 0xc0 0x4011c000 0x00 0x1000 0xc0 0x40120000 0x00 0x1000>;
					interrupts = <0x2f 0x04>;
					clocks = <0x02 0x16 0x02 0x29 0x02 0x2d 0x28 0x02 0x03>;
					clock-names = "cfgclk", "dpiclk", "byteclk", "refclk", "pllsys";
					assigned-clocks = <0x02 0x16>;
					assigned-clock-rates = <0x17d7840>;
					iommus = <0x3f>;
					phandle = <0xf1>;
				};
				dsi@128000 {
					compatible = "raspberrypi,rp1dsi";
					status = "disabled";
					reg = <0xc0 0x40130000 0x00 0x1000 0xc0 0x40134000 0x00 0x1000 0xc0 0x40138000 0x00 0x1000>;
					interrupts = <0x30 0x04>;
					clocks = <0x02 0x17 0x02 0x2a 0x02 0x2e 0x28 0x02 0x03>;
					clock-names = "cfgclk", "dpiclk", "byteclk", "refclk", "pllsys";
					assigned-clocks = <0x02 0x17>;
					assigned-clock-rates = <0x17d7840>;
					iommus = <0x3f>;
					phandle = <0xf2>;
				};
				vec@144000 {
					compatible = "raspberrypi,rp1vec";
					status = "disabled";
					reg = <0xc0 0x40144000 0x00 0x1000 0xc0 0x40140000 0x00 0x1000>;
					interrupts = <0x31 0x04>;
					clocks = <0x02 0x27>;
					assigned-clocks = <0x02 0x02 0x02 0x0b 0x02 0x27>;
					assigned-clock-rates = <0x46cf7100 0x66ff300 0x66ff300>;
					assigned-clock-parents = <0x00 0x02 0x02 0x02 0x0b>;
					iommus = <0x3f>;
					phandle = <0xf3>;
				};
				dpi@148000 {
					compatible = "raspberrypi,rp1dpi";
					status = "disabled";
					reg = <0xc0 0x40148000 0x00 0x1000 0xc0 0x40140000 0x00 0x1000>;
					interrupts = <0x31 0x04>;
					clocks = <0x02 0x28 0x02 0x05 0x02 0x02>;
					clock-names = "dpiclk", "plldiv", "pllcore";
					assigned-clocks = <0x02 0x28>;
					assigned-clock-parents = <0x02 0x05>;
					iommus = <0x3f>;
					phandle = <0xf4>;
				};
				sram@400000 {
					compatible = "mmio-sram";
					reg = <0xc0 0x40400000 0x00 0x10000>;
					#address-cells = <0x01>;
					#size-cells = <0x01>;
					ranges = <0x00 0xc0 0x40400000 0x10000>;
					phandle = <0xf5>;
					shmem@ff00 {
						compatible = "raspberrypi,rp1-shmem";
						reg = <0xff00 0x100>;
						phandle = <0x5d>;
					};
				};
				gpiomem@d0000 {
					compatible = "raspberrypi,gpiomem";
					reg = <0xc0 0x400d0000 0x00 0x30000>;
					chardev-name = "gpiomem0";
				};
			};
		};
	};
	leds {
		compatible = "gpio-leds";
		phandle = <0x102>;
		led-pwr {
			label = "PWR";
			gpios = <0x2d 0x2c 0x01>;
			default-state = "off";
			linux,default-trigger = "none";
			phandle = <0x6b>;
		};
		led-act {
			label = "ACT";
			gpios = <0x5a 0x09 0x01>;
			default-state = "off";
			linux,default-trigger = "mmc0";
			phandle = <0x5e>;
		};
	};
	rp1_firmware {
		compatible = "raspberrypi,rp1-firmware", "simple-mfd";
		mboxes = <0x5c 0x00>;
		shmem = <0x5d>;
		phandle = <0x40>;
	};
	chosen {
		stdout-path = "serial10:115200n8";
	};
	aliases {
		blconfig = "/reserved-memory/nvram@0";
		blpubkey = "/reserved-memory/nvram@1";
		console = "/soc@107c000000/serial@7d001000";
		drm-dsi1 = "/axi/pcie@1000120000/rp1/dsi@110000";
		drm-dsi2 = "/axi/pcie@1000120000/rp1/dsi@128000";
		ethernet0 = "/axi/pcie@1000120000/rp1/ethernet@100000";
		gpio0 = "/axi/pcie@1000120000/rp1/gpio@d0000";
		gpio3 = "/soc@107c000000/pinctrl@7d504100";
		gpiochip0 = "/axi/pcie@1000120000/rp1/gpio@d0000";
		i2c = "/axi/pcie@1000120000/rp1/i2c@74000";
		i2c0 = "/axi/pcie@1000120000/rp1/i2c@70000";
		i2c1 = "/axi/pcie@1000120000/rp1/i2c@74000";
		i2c2 = "/axi/pcie@1000120000/rp1/i2c@78000";
		i2c3 = "/axi/pcie@1000120000/rp1/i2c@7c000";
		i2c10 = "/axi/pcie@1000120000/rp1/i2c@88000";
		i2c11 = "/axi/pcie@1000120000/rp1/i2c@70000";
		pio0 = "/axi/pcie@1000120000/rp1/pio@178000";
		serial0 = "/axi/pcie@1000120000/rp1/serial@30000";
		serial1 = "/axi/pcie@1000120000/rp1/serial@34000";
		serial10 = "/soc@107c000000/serial@7d001000";
		serial2 = "/axi/pcie@1000120000/rp1/serial@38000";
		serial3 = "/axi/pcie@1000120000/rp1/serial@3c000";
		serial4 = "/axi/pcie@1000120000/rp1/serial@40000";
		spi0 = "/axi/pcie@1000120000/rp1/spi@50000";
		spi1 = "/axi/pcie@1000120000/rp1/spi@54000";
		spi2 = "/axi/pcie@1000120000/rp1/spi@58000";
		spi3 = "/axi/pcie@1000120000/rp1/spi@5c000";
		spi4 = "/axi/pcie@1000120000/rp1/spi@60000";
		spi5 = "/axi/pcie@1000120000/rp1/spi@64000";
		uart0 = "/axi/pcie@1000120000/rp1/serial@30000";
		uart1 = "/axi/pcie@1000120000/rp1/serial@34000";
		uart10 = "/soc@107c000000/serial@7d001000";
		uart2 = "/axi/pcie@1000120000/rp1/serial@38000";
		uart3 = "/axi/pcie@1000120000/rp1/serial@3c000";
		uart4 = "/axi/pcie@1000120000/rp1/serial@40000";
		usb0 = "/axi/pcie@1000120000/rp1/usb@200000";
		usb1 = "/axi/pcie@1000120000/rp1/usb@300000";
	};
	__symbols__ {
		rmem = "/reserved-memory";
		cma = "/reserved-memory/linux,cma";
		blconfig = "/reserved-memory/nvram@0";
		blpubkey = "/reserved-memory/nvram@1";
		soc = "/soc@107c000000";
		uart10 = "/soc@107c000000/serial@7d001000";
		pinctrl = "/soc@107c000000/pinctrl@7d504100";
		uarta_24_pins = "/soc@107c000000/pinctrl@7d504100/uarta_24_pins";
		sdio2_30_pins = "/soc@107c000000/pinctrl@7d504100/sdio2_30_pins";
		pwr_button_pins = "/soc@107c000000/pinctrl@7d504100/pwr_button_pins";
		wl_on_pins = "/soc@107c000000/pinctrl@7d504100/wl_on_pins";
		bt_shutdown_pins = "/soc@107c000000/pinctrl@7d504100/bt_shutdown_pins";
		emmc_ds_pull = "/soc@107c000000/pinctrl@7d504100/emmc_ds_pull";
		emmc_cmddat_pulls = "/soc@107c000000/pinctrl@7d504100/emmc_cmddat_pulls";
		spi10_pins = "/soc@107c000000/pinctrl@7d504100/spi10_gpio2";
		spi10_gpio2 = "/soc@107c000000/pinctrl@7d504100/spi10_gpio2";
		spi10_cs_pins = "/soc@107c000000/pinctrl@7d504100/spi10_cs_gpio1";
		spi10_cs_gpio1 = "/soc@107c000000/pinctrl@7d504100/spi10_cs_gpio1";
		axi = "/axi";
		pciex4 = "/axi/pcie@1000120000";
		rp1_target = "/axi/pcie@1000120000";
		pcie2 = "/axi/pcie@1000120000";
		rp1 = "/axi/pcie@1000120000/rp1";
		rp1_mbox = "/axi/pcie@1000120000/rp1/mailbox@8000";
		rp1_clocks = "/axi/pcie@1000120000/rp1/clocks@18000";
		uart0 = "/axi/pcie@1000120000/rp1/serial@30000";
		rp1_uart0 = "/axi/pcie@1000120000/rp1/serial@30000";
		uart1 = "/axi/pcie@1000120000/rp1/serial@34000";
		rp1_uart1 = "/axi/pcie@1000120000/rp1/serial@34000";
		uart2 = "/axi/pcie@1000120000/rp1/serial@38000";
		rp1_uart2 = "/axi/pcie@1000120000/rp1/serial@38000";
		uart3 = "/axi/pcie@1000120000/rp1/serial@3c000";
		rp1_uart3 = "/axi/pcie@1000120000/rp1/serial@3c000";
		uart4 = "/axi/pcie@1000120000/rp1/serial@40000";
		rp1_uart4 = "/axi/pcie@1000120000/rp1/serial@40000";
		rp1_uart5 = "/axi/pcie@1000120000/rp1/serial@44000";
		rp1_spi8 = "/axi/pcie@1000120000/rp1/spi@4c000";
		spi0 = "/axi/pcie@1000120000/rp1/spi@50000";
		rp1_spi0 = "/axi/pcie@1000120000/rp1/spi@50000";
		spidev0 = "/axi/pcie@1000120000/rp1/spi@50000/spidev@0";
		spidev1 = "/axi/pcie@1000120000/rp1/spi@50000/spidev@1";
		spi1 = "/axi/pcie@1000120000/rp1/spi@54000";
		rp1_spi1 = "/axi/pcie@1000120000/rp1/spi@54000";
		spi2 = "/axi/pcie@1000120000/rp1/spi@58000";
		rp1_spi2 = "/axi/pcie@1000120000/rp1/spi@58000";
		spi3 = "/axi/pcie@1000120000/rp1/spi@5c000";
		rp1_spi3 = "/axi/pcie@1000120000/rp1/spi@5c000";
		spi4 = "/axi/pcie@1000120000/rp1/spi@60000";
		rp1_spi4 = "/axi/pcie@1000120000/rp1/spi@60000";
		spi5 = "/axi/pcie@1000120000/rp1/spi@64000";
		rp1_spi5 = "/axi/pcie@1000120000/rp1/spi@64000";
		rp1_spi6 = "/axi/pcie@1000120000/rp1/spi@68000";
		rp1_spi7 = "/axi/pcie@1000120000/rp1/spi@6c000";
		i2c_csi_dsi = "/axi/pcie@1000120000/rp1/i2c@70000";
		i2c_csi_dsi1 = "/axi/pcie@1000120000/rp1/i2c@70000";
		i2c_vc = "/axi/pcie@1000120000/rp1/i2c@70000";
		i2c0 = "/axi/pcie@1000120000/rp1/i2c@70000";
		rp1_i2c0 = "/axi/pcie@1000120000/rp1/i2c@70000";
		i2c_arm = "/axi/pcie@1000120000/rp1/i2c@74000";
		i2c1 = "/axi/pcie@1000120000/rp1/i2c@74000";
		rp1_i2c1 = "/axi/pcie@1000120000/rp1/i2c@74000";
		i2c2 = "/axi/pcie@1000120000/rp1/i2c@78000";
		rp1_i2c2 = "/axi/pcie@1000120000/rp1/i2c@78000";
		i2c3 = "/axi/pcie@1000120000/rp1/i2c@7c000";
		rp1_i2c3 = "/axi/pcie@1000120000/rp1/i2c@7c000";
		i2c4 = "/axi/pcie@1000120000/rp1/i2c@80000";
		rp1_i2c4 = "/axi/pcie@1000120000/rp1/i2c@80000";
		i2c5 = "/axi/pcie@1000120000/rp1/i2c@84000";
		rp1_i2c5 = "/axi/pcie@1000120000/rp1/i2c@84000";
		i2c_csi_dsi0 = "/axi/pcie@1000120000/rp1/i2c@88000";
		i2c6 = "/axi/pcie@1000120000/rp1/i2c@88000";
		rp1_i2c6 = "/axi/pcie@1000120000/rp1/i2c@88000";
		rp1_audio_out = "/axi/pcie@1000120000/rp1/audio_out@94000";
		pwm = "/axi/pcie@1000120000/rp1/pwm@98000";
		pwm0 = "/axi/pcie@1000120000/rp1/pwm@98000";
		rp1_pwm0 = "/axi/pcie@1000120000/rp1/pwm@98000";
		pwm1 = "/axi/pcie@1000120000/rp1/pwm@9c000";
		rp1_pwm1 = "/axi/pcie@1000120000/rp1/pwm@9c000";
		i2s_clk_producer = "/axi/pcie@1000120000/rp1/i2s@a0000";
		i2s = "/axi/pcie@1000120000/rp1/i2s@a0000";
		rp1_i2s0 = "/axi/pcie@1000120000/rp1/i2s@a0000";
		i2s_clk_consumer = "/axi/pcie@1000120000/rp1/i2s@a4000";
		rp1_i2s1 = "/axi/pcie@1000120000/rp1/i2s@a4000";
		rp1_i2s2 = "/axi/pcie@1000120000/rp1/i2s@a8000";
		rp1_sdio_clk0 = "/axi/pcie@1000120000/rp1/sdio_clk0@b0004";
		rp1_sdio_clk1 = "/axi/pcie@1000120000/rp1/sdio_clk1@b4004";
		rp1_adc = "/axi/pcie@1000120000/rp1/adc@c8000";
		gpio = "/axi/pcie@1000120000/rp1/gpio@d0000";
		rp1_gpio = "/axi/pcie@1000120000/rp1/gpio@d0000";
		uart0_pins = "/axi/pcie@1000120000/rp1/gpio@d0000/rp1_uart0_14_15";
		rp1_uart0_14_15 = "/axi/pcie@1000120000/rp1/gpio@d0000/rp1_uart0_14_15";
		uart0_ctsrts_pins = "/axi/pcie@1000120000/rp1/gpio@d0000/rp1_uart0_ctsrts_16_17";
		rp1_uart0_ctsrts_16_17 = "/axi/pcie@1000120000/rp1/gpio@d0000/rp1_uart0_ctsrts_16_17";
		uart1_pins = "/axi/pcie@1000120000/rp1/gpio@d0000/rp1_uart1_0_1";
		rp1_uart1_0_1 = "/axi/pcie@1000120000/rp1/gpio@d0000/rp1_uart1_0_1";
		uart1_ctsrts_pins = "/axi/pcie@1000120000/rp1/gpio@d0000/rp1_uart1_ctsrts_2_3";
		rp1_uart1_ctsrts_2_3 = "/axi/pcie@1000120000/rp1/gpio@d0000/rp1_uart1_ctsrts_2_3";
		uart2_pins = "/axi/pcie@1000120000/rp1/gpio@d0000/rp1_uart2_4_5";
		rp1_uart2_4_5 = "/axi/pcie@1000120000/rp1/gpio@d0000/rp1_uart2_4_5";
		uart2_ctsrts_pins = "/axi/pcie@1000120000/rp1/gpio@d0000/rp1_uart2_ctsrts_6_7";
		rp1_uart2_ctsrts_6_7 = "/axi/pcie@1000120000/rp1/gpio@d0000/rp1_uart2_ctsrts_6_7";
		uart3_pins = "/axi/pcie@1000120000/rp1/gpio@d0000/rp1_uart3_8_9";
		rp1_uart3_8_9 = "/axi/pcie@1000120000/rp1/gpio@d0000/rp1_uart3_8_9";
		uart3_ctsrts_pins = "/axi/pcie@1000120000/rp1/gpio@d0000/rp1_uart3_ctsrts_10_11";
		rp1_uart3_ctsrts_10_11 = "/axi/pcie@1000120000/rp1/gpio@d0000/rp1_uart3_ctsrts_10_11";
		uart4_pins = "/axi/pcie@1000120000/rp1/gpio@d0000/rp1_uart4_12_13";
		rp1_uart4_12_13 = "/axi/pcie@1000120000/rp1/gpio@d0000/rp1_uart4_12_13";
		uart4_ctsrts_pins = "/axi/pcie@1000120000/rp1/gpio@d0000/rp1_uart4_ctsrts_14_15";
		rp1_uart4_ctsrts_14_15 = "/axi/pcie@1000120000/rp1/gpio@d0000/rp1_uart4_ctsrts_14_15";
		rp1_sdio0_22_27 = "/axi/pcie@1000120000/rp1/gpio@d0000/rp1_sdio0_22_27";
		rp1_sdio1_28_33 = "/axi/pcie@1000120000/rp1/gpio@d0000/rp1_sdio1_28_33";
		rp1_i2s0_18_21 = "/axi/pcie@1000120000/rp1/gpio@d0000/rp1_i2s0_18_21";
		rp1_i2s1_18_21 = "/axi/pcie@1000120000/rp1/gpio@d0000/rp1_i2s1_18_21";
		rp1_i2c4_34_35 = "/axi/pcie@1000120000/rp1/gpio@d0000/rp1_i2c4_34_35";
		rp1_i2c6_38_39 = "/axi/pcie@1000120000/rp1/gpio@d0000/rp1_i2c6_38_39";
		rp1_i2c4_40_41 = "/axi/pcie@1000120000/rp1/gpio@d0000/rp1_i2c4_40_41";
		rp1_i2c5_44_45 = "/axi/pcie@1000120000/rp1/gpio@d0000/rp1_i2c5_44_45";
		i2c0_pins = "/axi/pcie@1000120000/rp1/gpio@d0000/rp1_i2c0_0_1";
		rp1_i2c0_0_1 = "/axi/pcie@1000120000/rp1/gpio@d0000/rp1_i2c0_0_1";
		rp1_i2c0_8_9 = "/axi/pcie@1000120000/rp1/gpio@d0000/rp1_i2c0_8_9";
		i2c1_pins = "/axi/pcie@1000120000/rp1/gpio@d0000/rp1_i2c1_2_3";
		rp1_i2c1_2_3 = "/axi/pcie@1000120000/rp1/gpio@d0000/rp1_i2c1_2_3";
		rp1_i2c1_10_11 = "/axi/pcie@1000120000/rp1/gpio@d0000/rp1_i2c1_10_11";
		i2c2_pins = "/axi/pcie@1000120000/rp1/gpio@d0000/rp1_i2c2_4_5";
		rp1_i2c2_4_5 = "/axi/pcie@1000120000/rp1/gpio@d0000/rp1_i2c2_4_5";
		rp1_i2c2_12_13 = "/axi/pcie@1000120000/rp1/gpio@d0000/rp1_i2c2_12_13";
		i2c3_pins = "/axi/pcie@1000120000/rp1/gpio@d0000/rp1_i2c3_6_7";
		rp1_i2c3_6_7 = "/axi/pcie@1000120000/rp1/gpio@d0000/rp1_i2c3_6_7";
		rp1_i2c3_14_15 = "/axi/pcie@1000120000/rp1/gpio@d0000/rp1_i2c3_14_15";
		rp1_i2c3_22_23 = "/axi/pcie@1000120000/rp1/gpio@d0000/rp1_i2c3_22_23";
		dpi_16bit_gpio2 = "/axi/pcie@1000120000/rp1/gpio@d0000/rp1_dpi_16bit_gpio2";
		rp1_dpi_16bit_gpio2 = "/axi/pcie@1000120000/rp1/gpio@d0000/rp1_dpi_16bit_gpio2";
		dpi_16bit_cpadhi_gpio2 = "/axi/pcie@1000120000/rp1/gpio@d0000/rp1_dpi_16bit_cpadhi_gpio2";
		rp1_dpi_16bit_cpadhi_gpio2 = "/axi/pcie@1000120000/rp1/gpio@d0000/rp1_dpi_16bit_cpadhi_gpio2";
		rp1_dpi_16bit_pad666_gpio2 = "/axi/pcie@1000120000/rp1/gpio@d0000/rp1_dpi_16bit_pad666_gpio2";
		dpi_18bit_gpio2 = "/axi/pcie@1000120000/rp1/gpio@d0000/rp1_dpi_18bit_gpio2";
		rp1_dpi_18bit_gpio2 = "/axi/pcie@1000120000/rp1/gpio@d0000/rp1_dpi_18bit_gpio2";
		dpi_18bit_cpadhi_gpio2 = "/axi/pcie@1000120000/rp1/gpio@d0000/rp1_dpi_18bit_cpadhi_gpio2";
		rp1_dpi_18bit_cpadhi_gpio2 = "/axi/pcie@1000120000/rp1/gpio@d0000/rp1_dpi_18bit_cpadhi_gpio2";
		dpi_gpio1 = "/axi/pcie@1000120000/rp1/gpio@d0000/rp1_dpi_24bit_gpio2";
		rp1_dpi_24bit_gpio2 = "/axi/pcie@1000120000/rp1/gpio@d0000/rp1_dpi_24bit_gpio2";
		rp1_dpi_hvsync = "/axi/pcie@1000120000/rp1/gpio@d0000/rp1_dpi_hvsync";
		dpi_16bit_gpio0 = "/axi/pcie@1000120000/rp1/gpio@d0000/rp1_dpi_16bit_gpio0";
		rp1_dpi_16bit_gpio0 = "/axi/pcie@1000120000/rp1/gpio@d0000/rp1_dpi_16bit_gpio0";
		dpi_16bit_cpadhi_gpio0 = "/axi/pcie@1000120000/rp1/gpio@d0000/rp1_dpi_16bit_cpadhi_gpio0";
		rp1_dpi_16bit_cpadhi_gpio0 = "/axi/pcie@1000120000/rp1/gpio@d0000/rp1_dpi_16bit_cpadhi_gpio0";
		rp1_dpi_16bit_pad666_gpio0 = "/axi/pcie@1000120000/rp1/gpio@d0000/rp1_dpi_16bit_pad666_gpio0";
		dpi_18bit_gpio0 = "/axi/pcie@1000120000/rp1/gpio@d0000/rp1_dpi_18bit_gpio0";
		rp1_dpi_18bit_gpio0 = "/axi/pcie@1000120000/rp1/gpio@d0000/rp1_dpi_18bit_gpio0";
		dpi_18bit_cpadhi_gpio0 = "/axi/pcie@1000120000/rp1/gpio@d0000/rp1_dpi_18bit_cpadhi_gpio0";
		rp1_dpi_18bit_cpadhi_gpio0 = "/axi/pcie@1000120000/rp1/gpio@d0000/rp1_dpi_18bit_cpadhi_gpio0";
		dpi_gpio0 = "/axi/pcie@1000120000/rp1/gpio@d0000/rp1_dpi_24bit_gpio0";
		rp1_dpi_24bit_gpio0 = "/axi/pcie@1000120000/rp1/gpio@d0000/rp1_dpi_24bit_gpio0";
		rp1_gpclksrc0_gpio4 = "/axi/pcie@1000120000/rp1/gpio@d0000/rp1_gpclksrc0_gpio4";
		rp1_gpclksrc0_gpio20 = "/axi/pcie@1000120000/rp1/gpio@d0000/rp1_gpclksrc0_gpio20";
		rp1_gpclksrc1_gpio5 = "/axi/pcie@1000120000/rp1/gpio@d0000/rp1_gpclksrc1_gpio5";
		rp1_gpclksrc1_gpio18 = "/axi/pcie@1000120000/rp1/gpio@d0000/rp1_gpclksrc1_gpio18";
		rp1_gpclksrc1_gpio21 = "/axi/pcie@1000120000/rp1/gpio@d0000/rp1_gpclksrc1_gpio21";
		rp1_pwm1_gpio45 = "/axi/pcie@1000120000/rp1/gpio@d0000/rp1_pwm1_gpio45";
		spi0_pins = "/axi/pcie@1000120000/rp1/gpio@d0000/rp1_spi0_gpio9";
		rp1_spi0_gpio9 = "/axi/pcie@1000120000/rp1/gpio@d0000/rp1_spi0_gpio9";
		spi0_cs_pins = "/axi/pcie@1000120000/rp1/gpio@d0000/rp1_spi0_cs_gpio7";
		rp1_spi0_cs_gpio7 = "/axi/pcie@1000120000/rp1/gpio@d0000/rp1_spi0_cs_gpio7";
		rp1_spi1_gpio19 = "/axi/pcie@1000120000/rp1/gpio@d0000/rp1_spi1_gpio19";
		spi2_pins = "/axi/pcie@1000120000/rp1/gpio@d0000/rp1_spi2_gpio1";
		rp1_spi2_gpio1 = "/axi/pcie@1000120000/rp1/gpio@d0000/rp1_spi2_gpio1";
		spi3_pins = "/axi/pcie@1000120000/rp1/gpio@d0000/rp1_spi3_gpio5";
		rp1_spi3_gpio5 = "/axi/pcie@1000120000/rp1/gpio@d0000/rp1_spi3_gpio5";
		spi4_pins = "/axi/pcie@1000120000/rp1/gpio@d0000/rp1_spi4_gpio9";
		rp1_spi4_gpio9 = "/axi/pcie@1000120000/rp1/gpio@d0000/rp1_spi4_gpio9";
		spi5_pins = "/axi/pcie@1000120000/rp1/gpio@d0000/rp1_spi5_gpio13";
		rp1_spi5_gpio13 = "/axi/pcie@1000120000/rp1/gpio@d0000/rp1_spi5_gpio13";
		rp1_spi8_gpio49 = "/axi/pcie@1000120000/rp1/gpio@d0000/rp1_spi8_gpio49";
		rp1_spi8_cs_gpio52 = "/axi/pcie@1000120000/rp1/gpio@d0000/rp1_spi8_cs_gpio52";
		rp1_audio_out_12_13 = "/axi/pcie@1000120000/rp1/gpio@d0000/rp1_audio_out_12_13";
		usb_vbus_pins = "/axi/pcie@1000120000/rp1/gpio@d0000/usb_vbus_pins";
		eth0_irq_pins = "/axi/pcie@1000120000/rp1/gpio@d0000/eth0_irq_pins";
		rp1_eth = "/axi/pcie@1000120000/rp1/ethernet@100000";
		phy1 = "/axi/pcie@1000120000/rp1/ethernet@100000/ethernet-phy@0";
		csi0 = "/axi/pcie@1000120000/rp1/csi@110000";
		rp1_csi0 = "/axi/pcie@1000120000/rp1/csi@110000";
		csi1 = "/axi/pcie@1000120000/rp1/csi@128000";
		rp1_csi1 = "/axi/pcie@1000120000/rp1/csi@128000";
		pio = "/axi/pcie@1000120000/rp1/pio@178000";
		rp1_pio = "/axi/pcie@1000120000/rp1/pio@178000";
		rp1_mmc0 = "/axi/pcie@1000120000/rp1/mmc@180000";
		rp1_mmc1 = "/axi/pcie@1000120000/rp1/mmc@184000";
		rp1_dma = "/axi/pcie@1000120000/rp1/dma@188000";
		rp1_usb0 = "/axi/pcie@1000120000/rp1/usb@200000";
		rp1_usb1 = "/axi/pcie@1000120000/rp1/usb@300000";
		dsi0 = "/axi/pcie@1000120000/rp1/dsi@110000";
		rp1_dsi0 = "/axi/pcie@1000120000/rp1/dsi@110000";
		dsi1 = "/axi/pcie@1000120000/rp1/dsi@128000";
		rp1_dsi1 = "/axi/pcie@1000120000/rp1/dsi@128000";
		vec = "/axi/pcie@1000120000/rp1/vec@144000";
		rp1_vec = "/axi/pcie@1000120000/rp1/vec@144000";
		dpi = "/axi/pcie@1000120000/rp1/dpi@148000";
		rp1_dpi = "/axi/pcie@1000120000/rp1/dpi@148000";
		sram = "/axi/pcie@1000120000/rp1/sram@400000";
		rp1_fw_shmem = "/axi/pcie@1000120000/rp1/sram@400000/shmem@ff00";
		leds = "/leds";
		led_pwr = "/leds/led-pwr";
		led_act = "/leds/led-act";
		rp1_firmware = "/rp1_firmware";
	};
};
